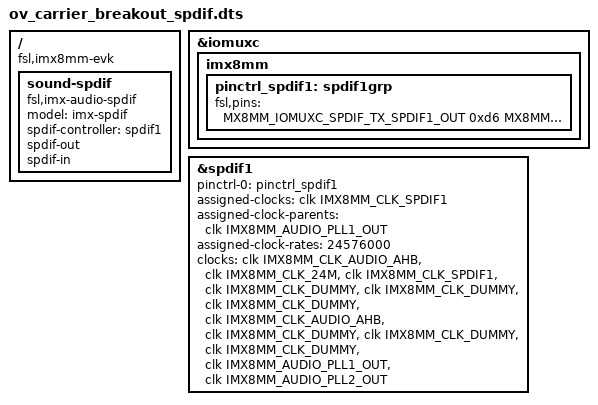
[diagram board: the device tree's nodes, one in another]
/**
 * Portenta-M8 dtb overlay file
 * Arduino 2021
 * Enable SPDIF on Arduino Breakout carrier board
 * A generic sound card is created to handle this interface
 */

/dts-v1/;
/plugin/;

#include "imx8mm-pinfunc.h"
#include <dt-bindings/clock/imx8mm-clock.h>

/ {
	compatible = "fsl,imx8mm-evk", "fsl,imx8mm";

	fragment@0 {
		target = <&iomuxc>;
		__overlay__ {
			imx8mm {
				pinctrl_spdif1: spdif1grp {
					fsl,pins = <
						MX8MM_IOMUXC_SPDIF_TX_SPDIF1_OUT			0xd6
						MX8MM_IOMUXC_SPDIF_RX_SPDIF1_IN				0xd6
					>;
				};
			};
		};
	};

	fragment@1 {
		target = <&spdif1>;
		__overlay__ {
			pinctrl-names = "default";
			pinctrl-0 = <&pinctrl_spdif1>;
			assigned-clocks = <&clk IMX8MM_CLK_SPDIF1>;
			assigned-clock-parents = <&clk IMX8MM_AUDIO_PLL1_OUT>;
			assigned-clock-rates = <24576000>;
			clocks = <&clk IMX8MM_CLK_AUDIO_AHB>, <&clk IMX8MM_CLK_24M>,
				<&clk IMX8MM_CLK_SPDIF1>, <&clk IMX8MM_CLK_DUMMY>,
				<&clk IMX8MM_CLK_DUMMY>, <&clk IMX8MM_CLK_DUMMY>,
				<&clk IMX8MM_CLK_AUDIO_AHB>, <&clk IMX8MM_CLK_DUMMY>,
				<&clk IMX8MM_CLK_DUMMY>, <&clk IMX8MM_CLK_DUMMY>,
				<&clk IMX8MM_AUDIO_PLL1_OUT>, <&clk IMX8MM_AUDIO_PLL2_OUT>;
			clock-names = "core", "rxtx0", "rxtx1", "rxtx2", "rxtx3",
				"rxtx4", "rxtx5", "rxtx6", "rxtx7", "spba", "pll8k", "pll11k";
			status = "okay";
		};
	};

	fragment@2 {
		target-path = "/";
		__overlay__ {
			sound-spdif {
				compatible = "fsl,imx-audio-spdif";
				model = "imx-spdif";
				spdif-controller = <&spdif1>;
				spdif-out;
				spdif-in;
			};
		};
	};
};
